# ESP32-S31 register map
Vendor: ESPRESSIF SYSTEMS (SHANGHAI) CO., LTD.; Series: ESP32 S-Series; File version: 1
CPU: RV32IMAFC r0p0, little endian, no MPU, FPU, 0 interrupt priority bits
Address unit: 32 bits
Registers are 32-bit, read-write, reset 0x0 unless marked. A register's access mark holds for its fields unless they carry their own. Offsets are from the block's base; [hi:lo] are bit positions; {n}, {i} and the like mark numbered series.

## LP_PWR — LP_PWR Peripheral
Base 0x20804000
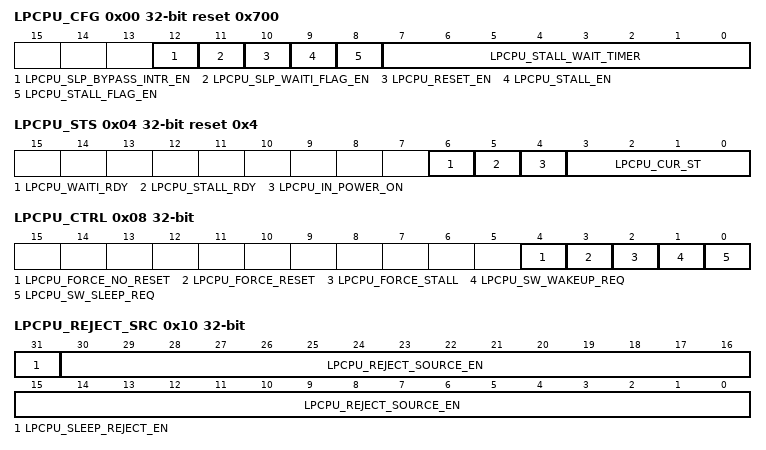
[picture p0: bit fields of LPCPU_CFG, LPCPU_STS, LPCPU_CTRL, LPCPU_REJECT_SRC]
0x00 LPCPU_CFG reset 0x700 — config register for lpcpu power control
  [12] LPCPU_SLP_BYPASS_INTR_EN — 1: enable interrupt bypass signal for lpcpu during lpcpu power off sequence 0: disable interrupt bypass signal for lpcpu during lpcpu power off sequence
  [11] LPCPU_SLP_WAITI_FLAG_EN — 1: validates lp cpu waiti rdy signal during lpcpu power off sequence 0: invalidates lp cpu waiti rdy signal during lpcpu power off sequence
  [10] LPCPU_RESET_EN — 1: enable lpcpu reset during lpcpu power off sequence 0: disable lpcpu reset during lpcpu power off sequence
  [9] LPCPU_STALL_EN — 1: enable lpcpu stall during lpcpu power off sequence 0: disable lpcpu stall during lpcpu power off sequence
  [8] LPCPU_STALL_FLAG_EN — 1: wait for stall rdy input during lpcpu power off sequence 0:do not wait for stall rdy during lpcpu power off sequence
  [7:0] LPCPU_STALL_WAIT_TIMER — stall wait timer for lpcpu during lpcpu power off sequence
0x04 LPCPU_STS ro reset 0x4 — status register for LPCPU PWR
  [6] LPCPU_WAITI_RDY — 1:lpcpu stall waiti ready 0:lpcpu stall waiti ready
  [5] LPCPU_STALL_RDY — 1:lpcpu stall not ready 0:lpcpu stall ready
  [4] LPCPU_IN_POWER_ON — 1:lpcpu current in power on mode 0:lpcpu not in power on mode
  [3:0] LPCPU_CUR_ST — current power state register for lpcpu
0x08 LPCPU_CTRL access per field — ctrl register for lpcpu power control
  [4] LPCPU_FORCE_NO_RESET rw — 1: force no reset lpcpu 0: no change
  [3] LPCPU_FORCE_RESET rw — 1: force reset lpcpu 0: no change
  [2] LPCPU_FORCE_STALL rw — 1: force stall lpcpu 0: no change
  [1] LPCPU_SW_WAKEUP_REQ wo — software wakeup request config for lpcpu
  [0] LPCPU_SW_SLEEP_REQ wo — software sleep request config for lpcpu
0x0C LPCPU_WAKEUP_SRC — wakeup source register for lpcpu
  [30:0] LPCPU_WAKEUP_SOURCE_EN — wakeup source enable signal for lpcpu
0x10 LPCPU_REJECT_SRC — reject source register for lpcpu
  [31] LPCPU_SLEEP_REJECT_EN — 1: sleep request can be rejected 0: sleep request cannot be rejected
  [30:0] LPCPU_REJECT_SOURCE_EN — reject source enable signal for lpcpu
0x14 LPCPU_WAKEUP_CAUSE ro — wakeup cause register for lpcpu
  [30:0] LPCPU_WAKEUP_CAUSE — wakeup cause for lpcpu
0x18 LPCPU_REJECT_CAUSE ro — reject cause register for lpcpu
  [30:0] LPCPU_REJECT_CAUSE — reject cause for lpcpu
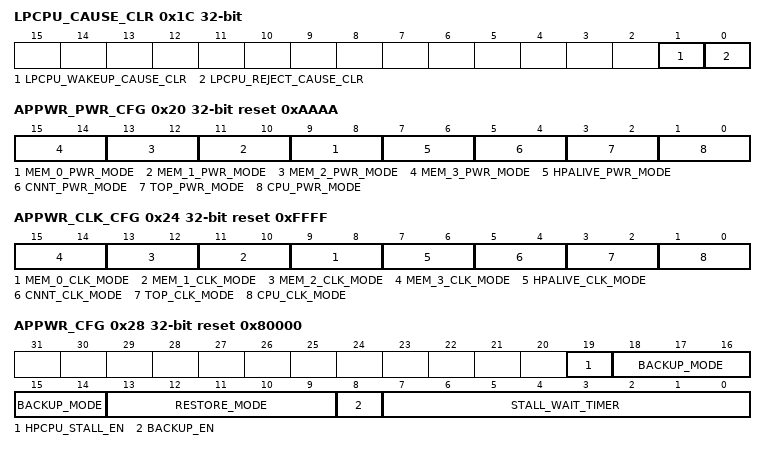
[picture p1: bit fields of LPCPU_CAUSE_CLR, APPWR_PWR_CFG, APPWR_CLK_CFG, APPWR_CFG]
0x1C LPCPU_CAUSE_CLR wo — cause clear register for lpcpu
  [1] LPCPU_WAKEUP_CAUSE_CLR — wakeup cause clear signal for lpcpu
  [0] LPCPU_REJECT_CAUSE_CLR — reject cause clear signal for lpcpu
0x20 APPWR_PWR_CFG reset 0xAAAA — config register for apsys pwr and clk mode
  [2n+9:2n+8] MEM_{n}_PWR_MODE (n=0..3) — mem_{n} pwr mode config register for apsys
  [7:6] HPALIVE_PWR_MODE — hpalive pwr mode config register for apsys
  [5:4] CNNT_PWR_MODE — cnnt pwr mode config register for apsys
  [3:2] TOP_PWR_MODE — top pwr mode config register for apsys
  [1:0] CPU_PWR_MODE — cpu pwr mode config register for apsys
0x24 APPWR_CLK_CFG reset 0xFFFF — config register for apsys pwr and clk mode
  [2n+9:2n+8] MEM_{n}_CLK_MODE (n=0..3) — mem_{n} clk mode config register for apsys
  [7:6] HPALIVE_CLK_MODE — hpalive clk mode config register for apsys
  [5:4] CNNT_CLK_MODE — cnnt clk mode config register for apsys
  [3:2] TOP_CLK_MODE — top clk mode config register for apsys
  [1:0] CPU_CLK_MODE — cpu clk mode config register for apsys
0x28 APPWR_CFG reset 0x80000 — config register for apsys pwr
  [19] HPCPU_STALL_EN — 1: enable hpcpu stall 0: disable hpcpu stall
  [18:14] BACKUP_MODE — backup mode config register for apsys
  [13:9] RESTORE_MODE — restore mode config register for apsys
  [8] BACKUP_EN — the backup enable config register for ap sys
  [7:0] STALL_WAIT_TIMER — the wait timer config for ap sys
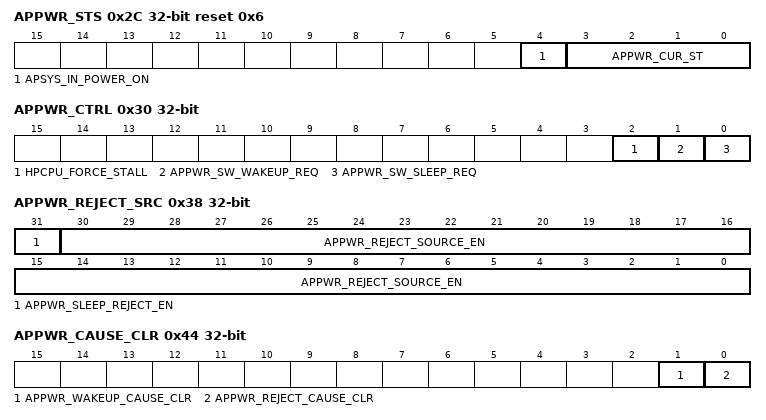
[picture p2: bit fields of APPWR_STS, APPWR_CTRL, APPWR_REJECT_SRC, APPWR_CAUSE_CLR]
0x2C APPWR_STS ro reset 0x6 — status register for apsys pwr
  [4] APSYS_IN_POWER_ON — 1:apsys current in power on mode 0:apsys not in power on mode
  [3:0] APPWR_CUR_ST — current power state register for apsys
0x30 APPWR_CTRL access per field — ctrl register for appwr power control
  [2] HPCPU_FORCE_STALL rw — 1: force stall hpcpu 0: no change
  [1] APPWR_SW_WAKEUP_REQ wo — software wakeup request config for appwr
  [0] APPWR_SW_SLEEP_REQ wo — software sleep request config for appwr
0x34 APPWR_WAKEUP_SRC — wakeup source register for appwr
  [30:0] APPWR_WAKEUP_SOURCE_EN — wakeup enable signal for appwr
0x38 APPWR_REJECT_SRC — reject source register for appwr
  [31] APPWR_SLEEP_REJECT_EN — 1: sleep request can be rejected 0: sleep request cannot be rejected
  [30:0] APPWR_REJECT_SOURCE_EN — reject enable signal for appwr
0x3C APPWR_WAKEUP_CAUSE ro — wakeup cause register for appwr
  [30:0] APPWR_WAKEUP_CAUSE — wakeup cause for appwr
0x40 APPWR_REJECT_CAUSE ro — reject cause register for appwr
  [30:0] APPWR_REJECT_CAUSE — reject cause for appwr
0x44 APPWR_CAUSE_CLR wo — cause clear register for appwr
  [1] APPWR_WAKEUP_CAUSE_CLR — wakeup cause clear signal for appwr
  [0] APPWR_REJECT_CAUSE_CLR — reject cause clear signal for appwr
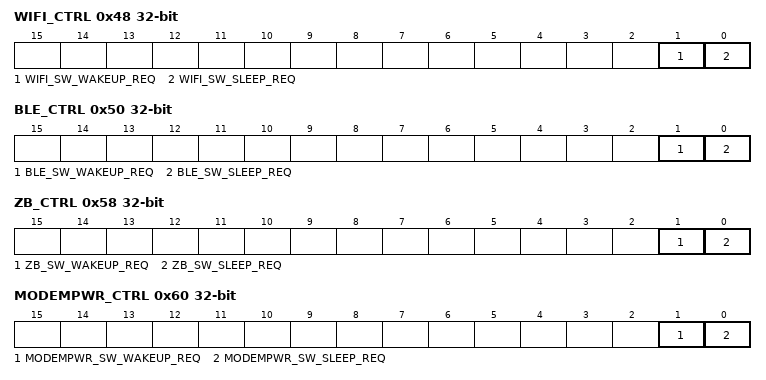
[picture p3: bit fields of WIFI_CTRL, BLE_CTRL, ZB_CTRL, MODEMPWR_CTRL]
0x48 WIFI_CTRL wo — ctrl register for wifi power control
  [1] WIFI_SW_WAKEUP_REQ — software wakeup request config for wifi
  [0] WIFI_SW_SLEEP_REQ — software sleep request config for wifi
0x4C WIFI_WAKEUP_SRC — wakeup source register for wifi
  [30:0] WIFI_WAKEUP_SOURCE_EN — wakeup enable signal for wifi
0x50 BLE_CTRL wo — ctrl register for ble power control
  [1] BLE_SW_WAKEUP_REQ — software wakeup request config for ble
  [0] BLE_SW_SLEEP_REQ — software sleep request config for ble
0x54 BLE_WAKEUP_SRC — wakeup source register for ble
  [30:0] BLE_WAKEUP_SOURCE_EN — wakeup enable signal for ble
0x58 ZB_CTRL wo — ctrl register for zb power control
  [1] ZB_SW_WAKEUP_REQ — software wakeup request config for zb
  [0] ZB_SW_SLEEP_REQ — software sleep request config for zb
0x5C ZB_WAKEUP_SRC — wakeup source register for zb
  [30:0] ZB_WAKEUP_SOURCE_EN — wakeup enazb signal for zb
0x60 MODEMPWR_CTRL wo — ctrl register for modempwr power control
  [1] MODEMPWR_SW_WAKEUP_REQ — software wakeup request config for modempwr
  [0] MODEMPWR_SW_SLEEP_REQ — software sleep request config for modempwr
0x64 MODEMPWR_WAKEUP_SRC — wakeup source register for modempwr
  [30:0] MODEMPWR_WAKEUP_SOURCE_EN — wakeup enable signal for modempwr
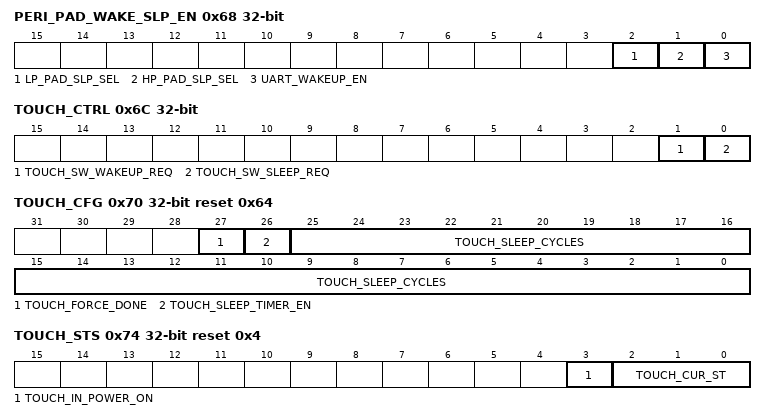
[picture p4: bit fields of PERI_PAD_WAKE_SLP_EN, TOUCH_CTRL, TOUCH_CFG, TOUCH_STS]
0x68 PERI_PAD_WAKE_SLP_EN — used for future potential eco, others don't care
  [2] LP_PAD_SLP_SEL — 1:hppad will sleep after hpcpu stall 0:hppad will not sleep after hpcpu stall
  [1] HP_PAD_SLP_SEL — 1:hppad will sleep after hpcpu stall 0:hppad will not sleep after hpcpu stall
  [0] UART_WAKEUP_EN — 1:enables uart wakeup after hpcpu stall 0:disables uart wakeup after hpcpu stall
0x6C TOUCH_CTRL wo — ctrl register for touch power control
  [1] TOUCH_SW_WAKEUP_REQ — software wakeup request config for touch
  [0] TOUCH_SW_SLEEP_REQ — software sleep request config for touch
0x70 TOUCH_CFG reset 0x64 — ctrl register for touch power control
  [27] TOUCH_FORCE_DONE — 1: force touch task to done state, turn off touch 0: no effect
  [26] TOUCH_SLEEP_TIMER_EN — 1:enables touch timer wakeup source 0:disables touch timer wakeup source
  [25:0] TOUCH_SLEEP_CYCLES — sleep cycles config for touch
0x74 TOUCH_STS ro reset 0x4 — status register for TOUCH PWR
  [3] TOUCH_IN_POWER_ON — 1:touch current in power on mode 0:touch not in power on mode
  [2:0] TOUCH_CUR_ST — current power state register for touch
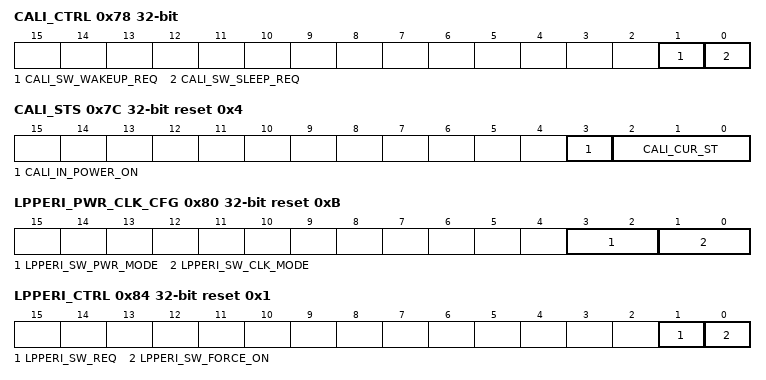
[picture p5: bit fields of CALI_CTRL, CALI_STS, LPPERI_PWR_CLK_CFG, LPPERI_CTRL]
0x78 CALI_CTRL wo — ctrl register for cali power control
  [1] CALI_SW_WAKEUP_REQ — software wakeup request config for cali
  [0] CALI_SW_SLEEP_REQ — software sleep request config for cali
0x7C CALI_STS ro reset 0x4 — status register for CALI PWR
  [3] CALI_IN_POWER_ON — 1:cali current in power on mode 0:cali not in power on mode
  [2:0] CALI_CUR_ST — current power state register for cali
0x80 LPPERI_PWR_CLK_CFG reset 0xB — ctrl register for lpcpu power clock mode control
  [3:2] LPPERI_SW_PWR_MODE — software configs LPPERI pwr mode
  [1:0] LPPERI_SW_CLK_MODE — software configs LPPERI clk mode
0x84 LPPERI_CTRL access per field reset 0x1 — ctrl register for lpperi power control
  [1] LPPERI_SW_REQ wo — software req pulse for following mode register
  [0] LPPERI_SW_FORCE_ON rw — 1: software wake lpperi
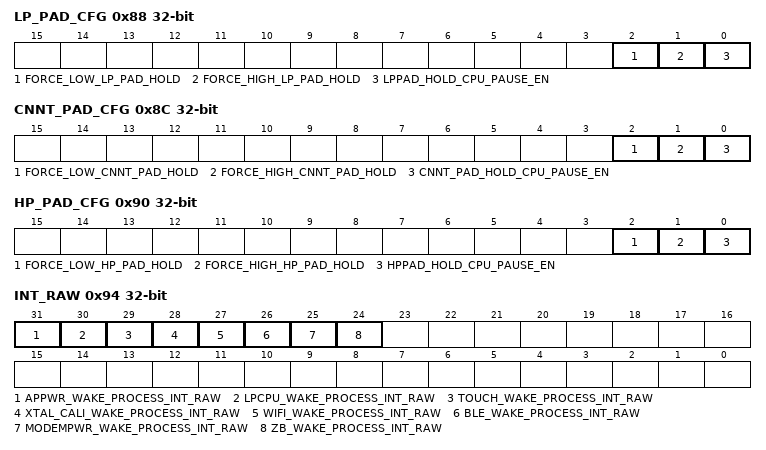
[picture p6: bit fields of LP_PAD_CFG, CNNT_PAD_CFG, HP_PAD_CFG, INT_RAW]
0x88 LP_PAD_CFG — config register for lppad hold signal
  [2] FORCE_LOW_LP_PAD_HOLD — 1:force pull low lppad hold signal 0:no effect
  [1] FORCE_HIGH_LP_PAD_HOLD — 1:force pull up lppad hold signal 0:no effect
  [0] LPPAD_HOLD_CPU_PAUSE_EN — 1: hold lppad when hpcpu stalls 0: not hold lppad when hpcpu stalls
0x8C CNNT_PAD_CFG — config register for cnntpad hold signal
  [2] FORCE_LOW_CNNT_PAD_HOLD — 1:force pull low cnntpad hold signal 0:no effect
  [1] FORCE_HIGH_CNNT_PAD_HOLD — 1:force pull up cnntpad hold signal 0:no effect
  [0] CNNT_PAD_HOLD_CPU_PAUSE_EN — 1: hold cnntpad when hpcpu stalls 0: not hold cnntpad when hpcpu stalls
0x90 HP_PAD_CFG — config register for hppad hold signal
  [2] FORCE_LOW_HP_PAD_HOLD — 1:force pull low hppad hold signal 0:no effect
  [1] FORCE_HIGH_HP_PAD_HOLD — 1:force pull up hppad hold signal 0:no effect
  [0] HPPAD_HOLD_CPU_PAUSE_EN — 1: hold hppad when hpcpu stalls 0: not hold hppad when hpcpu stalls
0x94 INT_RAW — need_des
  [31] APPWR_WAKE_PROCESS_INT_RAW — need_des
  [30] LPCPU_WAKE_PROCESS_INT_RAW — need_des
  [29] TOUCH_WAKE_PROCESS_INT_RAW — need_des
  [28] XTAL_CALI_WAKE_PROCESS_INT_RAW — need_des
  [27] WIFI_WAKE_PROCESS_INT_RAW — need_des
  [26] BLE_WAKE_PROCESS_INT_RAW — need_des
  [25] MODEMPWR_WAKE_PROCESS_INT_RAW — need_des
  [24] ZB_WAKE_PROCESS_INT_RAW — need_des
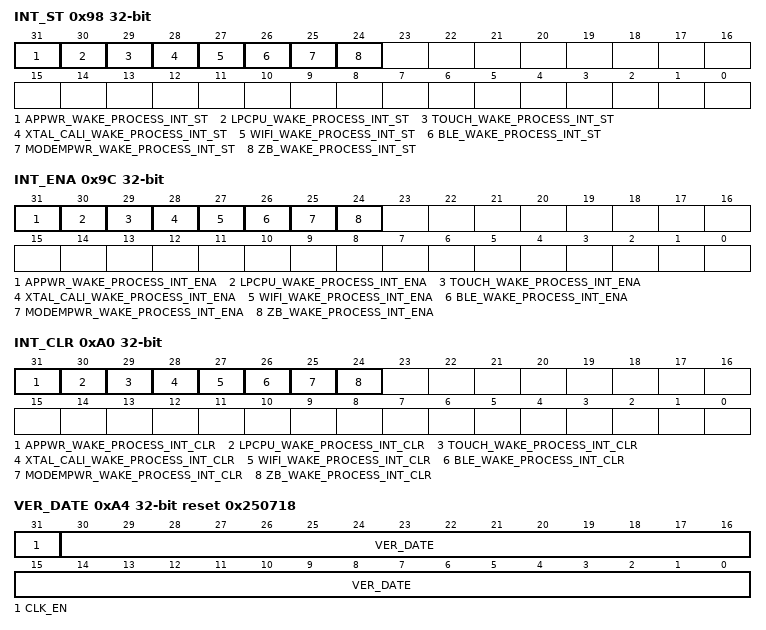
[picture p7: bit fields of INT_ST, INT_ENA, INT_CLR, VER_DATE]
0x98 INT_ST ro — need_des
  [31] APPWR_WAKE_PROCESS_INT_ST — need_des
  [30] LPCPU_WAKE_PROCESS_INT_ST — need_des
  [29] TOUCH_WAKE_PROCESS_INT_ST — need_des
  [28] XTAL_CALI_WAKE_PROCESS_INT_ST — need_des
  [27] WIFI_WAKE_PROCESS_INT_ST — need_des
  [26] BLE_WAKE_PROCESS_INT_ST — need_des
  [25] MODEMPWR_WAKE_PROCESS_INT_ST — need_des
  [24] ZB_WAKE_PROCESS_INT_ST — need_des
0x9C INT_ENA — need_des
  [31] APPWR_WAKE_PROCESS_INT_ENA — need_des
  [30] LPCPU_WAKE_PROCESS_INT_ENA — need_des
  [29] TOUCH_WAKE_PROCESS_INT_ENA — need_des
  [28] XTAL_CALI_WAKE_PROCESS_INT_ENA — need_des
  [27] WIFI_WAKE_PROCESS_INT_ENA — need_des
  [26] BLE_WAKE_PROCESS_INT_ENA — need_des
  [25] MODEMPWR_WAKE_PROCESS_INT_ENA — need_des
  [24] ZB_WAKE_PROCESS_INT_ENA — need_des
0xA0 INT_CLR wo — need_des
  [31] APPWR_WAKE_PROCESS_INT_CLR — need_des
  [30] LPCPU_WAKE_PROCESS_INT_CLR — need_des
  [29] TOUCH_WAKE_PROCESS_INT_CLR — need_des
  [28] XTAL_CALI_WAKE_PROCESS_INT_CLR — need_des
  [27] WIFI_WAKE_PROCESS_INT_CLR — need_des
  [26] BLE_WAKE_PROCESS_INT_CLR — need_des
  [25] MODEMPWR_WAKE_PROCESS_INT_CLR — need_des
  [24] ZB_WAKE_PROCESS_INT_CLR — need_des
0xA4 VER_DATE reset 0x250718 — need_des
  [31] CLK_EN — need_des
  [30:0] VER_DATE — need_des
